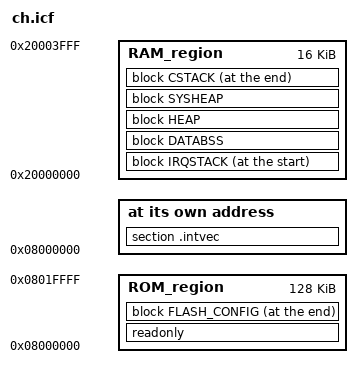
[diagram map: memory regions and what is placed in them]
/*###ICF### Section handled by ICF editor, don't touch! ****/
/*-Editor annotation file-*/
/* IcfEditorFile="$TOOLKIT_DIR$\config\ide\IcfEditor\cortex_v1_0.xml" */
/*-Specials-*/
define symbol __ICFEDIT_intvec_start__ = 0x08000000;
/*-Memory Regions-*/
define symbol __ICFEDIT_region_ROM_start__ = 0x08000000;
define symbol __ICFEDIT_region_ROM_end__   = 0x0801FFFF;
define symbol __ICFEDIT_region_RAM_start__ = 0x20000000;
define symbol __ICFEDIT_region_RAM_end__   = 0x20003FFF;
/*-Sizes-*/
define symbol __ICFEDIT_size_cstack__ = 0x400;
define symbol __ICFEDIT_size_heap__   = 0x400;
/**** End of ICF editor section. ###ICF###*/

/* Size of the IRQ Stack (Main Stack).*/
define symbol __ICFEDIT_size_irqstack__   = 0x400;

define symbol __ICFEDIT_flash_page_size__ = 0x800;

define memory mem with size = 4G;
define region ROM_region   = mem:[from __ICFEDIT_region_ROM_start__   to __ICFEDIT_region_ROM_end__];
define region RAM_region   = mem:[from __ICFEDIT_region_RAM_start__   to __ICFEDIT_region_RAM_end__];

define block CSTACK    with alignment = 8, size = __ICFEDIT_size_cstack__   {section CSTACK};
define block IRQSTACK  with alignment = 8, size = __ICFEDIT_size_irqstack__ {};
define block HEAP      with alignment = 8, size = __ICFEDIT_size_heap__     { };
define block SYSHEAP   with alignment = 8                                   {section SYSHEAP};
define block DATABSS   with alignment = 8 {readwrite, zeroinit};


define block FLASH_CONFIG_MAIN  with alignment = __ICFEDIT_flash_page_size__, size = 0x0800 { readonly section FLASH_CONFIG_MAIN  };
define block FLASH_CONFIG_SAVE0 with alignment = __ICFEDIT_flash_page_size__, size = 0x1800 { readonly section FLASH_CONFIG_SAVE0 };
define block FLASH_CONFIG_SAVE1 with alignment = __ICFEDIT_flash_page_size__, size = 0x1800 { readonly section FLASH_CONFIG_SAVE1 };
define block FLASH_CONFIG_SAVE2 with alignment = __ICFEDIT_flash_page_size__, size = 0x1800 { readonly section FLASH_CONFIG_SAVE2 };
define block FLASH_CONFIG_SAVE3 with alignment = __ICFEDIT_flash_page_size__, size = 0x1800 { readonly section FLASH_CONFIG_SAVE3 };
define block FLASH_CONFIG_SAVE4 with alignment = __ICFEDIT_flash_page_size__, size = 0x1800 { readonly section FLASH_CONFIG_SAVE4 };
define block FLASH_CONFIG with fixed order, alignment = __ICFEDIT_flash_page_size__
{
    block FLASH_CONFIG_MAIN,
    block FLASH_CONFIG_SAVE0,
    block FLASH_CONFIG_SAVE1,
    block FLASH_CONFIG_SAVE2,
    block FLASH_CONFIG_SAVE3,
    block FLASH_CONFIG_SAVE4,
};

initialize by copy { readwrite };
do not initialize  { section .noinit };

keep { section .intvec };

place at address mem:__ICFEDIT_intvec_start__ {section .intvec};
place in ROM_region                           {readonly};
place at start of RAM_region                  {block IRQSTACK};
place in RAM_region                           {block DATABSS, block HEAP};
place in RAM_region                           {block SYSHEAP};
place at end of RAM_region                    {block CSTACK};
place at end of ROM_region                    {block FLASH_CONFIG};

export symbol __ICFEDIT_region_RAM_start__;
export symbol __ICFEDIT_region_RAM_end__;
